# ATA5700M322 device description
Architecture: AVR8; Family: megaAVR
Registers are 8-bit, access not given, no defined reset value unless marked. A register's access mark holds for its fields unless they carry their own. Offsets are from the block's base; [hi:lo] are bit positions; {n}, {i} and the like mark numbered series.

## CRC
Instances: CRC 0x00
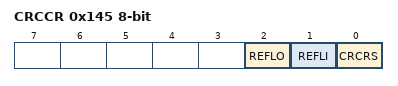
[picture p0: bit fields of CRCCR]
0x145 CRCCR — CRC Control Register
  [2] REFLO — Reflect Data Output Byte
  [1] REFLI — Reflect Data Input Byte
  [0] CRCRS — CRC Data Register Reset
0x146 CRCDOR — CRC Data Output Register
0x1E0 CRCDIR — CRC Data Input Register

## DEBOUNCE
Instances: DEBOUNCE 0x00
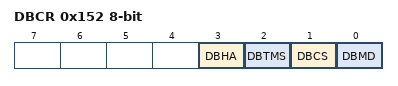
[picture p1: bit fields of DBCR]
0x152 DBCR — DeBounce Control Register
  [3] DBHA — Debounce Handshake Active
  [2] DBTMS — Debounce Timer Mask Select
  [1] DBCS — Debounce Clock Select
  [0] DBMD — Debounce Mode
0x153 DBTC — Debounce Timer Compare Register
0x154 DBENB — DeBounce Enable Port B
0x155 DBENC bits used 2:0 — DeBounce Enable Port C
0x164 DBEND — DeBounce Enable Port D

## DEBUG
Instances: DEBUG 0x00
0xFC TRCID 16-bit — Trace ID Register
0xFF TRCDR — Trace Data Register
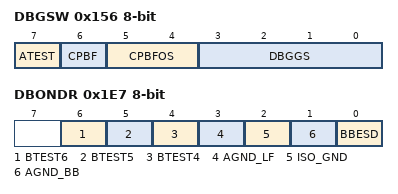
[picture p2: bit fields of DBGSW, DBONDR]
0x156 DBGSW — Debugging Support Switch
  [7] ATEST — Analog Test Pins Enable
  [6] CPBF — CPU Busy Flag
  [5:4] CPBFOS — CPU Busy Flag Output Select
    0=disabled; 1=PB0; 2=PB3; 3=PC1
  [3:0] DBGGS — Debugging Support Group Select
0x1E7 DBONDR — Downbond Test Register
  [6] BTEST6 — Bond Test 6
  [5] BTEST5 — Bond Test 5
  [4] BTEST4 — Bond Test 4
  [3] AGND_LF — Bond AGND LF
  [2] ISO_GND — Bond ISO SUBS3 GND
  [1] AGND_BB — Bond AGND BB
  [0] BBESD — Bond BBESD

## DFIFO
Instances: DFIFO 0x00
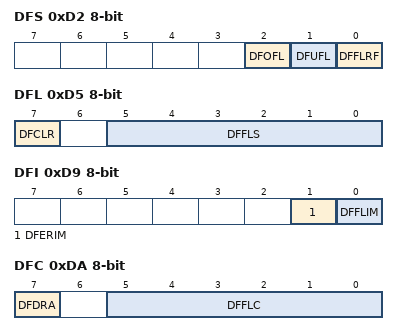
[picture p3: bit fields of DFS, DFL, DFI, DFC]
0xD2 DFS — Data FIFO Status Register
  [2] DFOFL — Data FIFO Overflow Flag
  [1] DFUFL — Data FIFO Underflow Flag
  [0] DFFLRF — Data FIFO Fill-Level Reached Status Flag
0xD5 DFL — Data FIFO Fill Level Register
  [7] DFCLR — Data FIFO Clear
  [5:0] DFFLS — Data FIFO Fill Level Status
0xD6 DFWP bits used 5:0 — Data FIFO Write Pointer
0xD7 DFRP bits used 5:0 — Data FIFO Read Pointer
0xD8 DFD — Data FIFO Data Register
0xD9 DFI — Data FIFO Interrupt Mask Register
  [1] DFERIM — Data FIFO Error Interrupt Mask
  [0] DFFLIM — Data FIFO Fill-level Interrupt Mask
0xDA DFC — Data FIFO Configuration Register
  [7] DFDRA — Data FIFO Direct Read Access Operational Mode
  [5:0] DFFLC — Data FIFO Fill-Level Configuration

## EEPROM
Instances: EEPROM 0x00
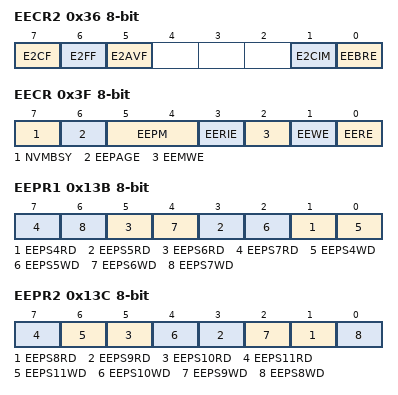
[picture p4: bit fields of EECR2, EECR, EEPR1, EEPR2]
0x36 EECR2 — EEPROM Control Register 2
  [7] E2CF — EEPROM Error Correction Code Flag
  [6] E2FF — EEPROM error Fault Flag bit
  [5] E2AVF — EEPROM Access Violation Flag
  [1] E2CIM — EEPROM Error Code Correction Interrupt Mask
  [0] EEBRE — EEPROM Burst Read Enable
0x3F EECR — EEPROM Control Register
  [7] NVMBSY — Non-volatile memory busy
  [6] EEPAGE — EEPROM page access (multiple bytes access mode)
  [5:4] EEPM — EEPROM Programming Mode
    0=Erase and Write in one operation; 1=Erase Only; 2=Write Only
  [3] EERIE — EEPROM Ready Interrupt Enable
  [2] EEMWE — EEPROM Master Write Enable
  [1] EEWE — EEPROM Write Enable
  [0] EERE — EEPROM Read Enable
0x40 EEDR — EEPROM Data Register
0x41 EEAR 16-bit bits used 11:0 — EEPROM Address Register
0x43 EEPR — EEPROM Protection Register
  [3:0] EEAP — EEPROM Access Protection
0x13B EEPR1 — EEPROM Protection Register 1
  [2n-7] EEPS{n}RD (n=4..7) — EEPROM Protection Section {n} Read Disable
  [2n-8] EEPS{n}WD (n=4..7) — EEPROM Protection Section {n} Write Disable
0x13C EEPR2 — EEPROM Protection Register 2
  [2n-15] EEPS{n}RD (n=8..11) — EEPROM Protection Section {n} Read Disable
  [6] EEPS11WD — EEPROM Protection Section 11 Write Disable
  [4] EEPS10WD — EEPROM Protection Section 10 Write Disableble
  [2] EEPS9WD — EEPROM Protection Section 9 Write Disable
  [0] EEPS8WD — EEPROM Protection Section 8 Write Disable
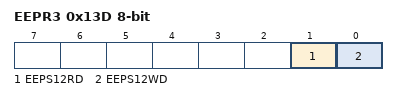
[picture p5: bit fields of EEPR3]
0x13D EEPR3 — EEPROM Protection Register 3
  [1] EEPS12RD — EEPROM Protection Section 12 Read Disable
  [0] EEPS12WD — EEPROM Protection Section 12 Write Disable

## GPIOREGS_DVCC
Instances: GPIOREGS_DVCC 0x00
0x20 GPIOR0 — General Purpose I/O Register 0
0x44 GPIOR1 — General Purpose I/O Register 1
0x45 GPIOR2 — General Purpose I/O Register 2
